# K510 register map
Vendor: Canaan; File version: 1.0
Registers are 32-bit, read-write, reset 0x0 unless marked. A register's access mark holds for its fields unless they carry their own. Offsets are from the block's base; [hi:lo] are bit positions; lines under a group give offsets from that group; {n}, {i} and the like mark numbered series; 'fields as' and 'values as' point back to an identical list.

## SYSCTL — System Control
Base 0x97000000
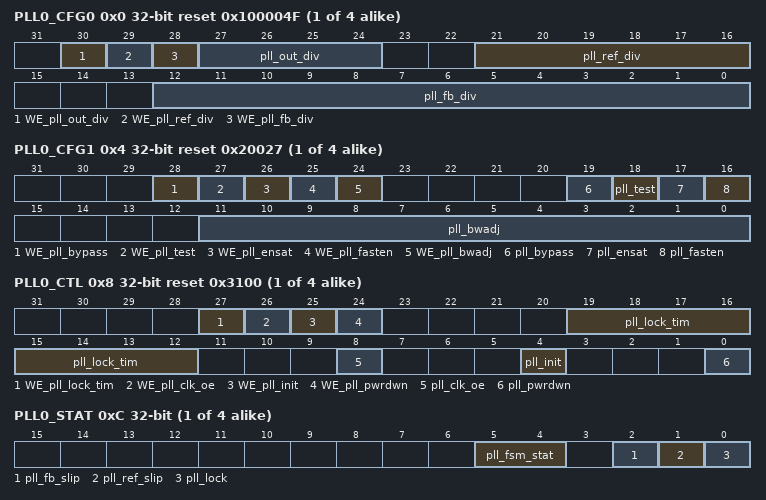
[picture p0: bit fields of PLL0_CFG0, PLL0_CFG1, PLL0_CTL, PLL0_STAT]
{0x0+0x10*i} PLL{i}_CFG0 (i=0..3) reset 0x100004F (reset mask 0x7F3F1FFFF) — PLL[i] configuration register 0
  [30] WE_pll_out_div wo — Write enable for bits [27:24] (pll_out_div)
  [29] WE_pll_ref_div wo — Write enable for bits [21:16] (pll_ref_div)
  [28] WE_pll_fb_div wo — Write enable for bits [12:0] (pll_fb_div)
  [27:24] pll_out_div — PLL[i] VCO output clock post division ratio. It is strongly suggested not to modify this value.
  [21:16] pll_ref_div — PLL[i] reference clock path division ratio.
  [12:0] pll_fb_div — PLL[i] feedback path clock division ratio.
{0x4+0x10*i} PLL{i}_CFG1 (i=0..3) reset 0x20027 — PLL[i] configuration register 1
  [28] WE_pll_bypass wo — Write enable for bit 19 (pll_bypass)
  [27] WE_pll_test wo — Write enable for bit 18 (pll_test)
  [26] WE_pll_ensat wo — Write enable for bit 17 (pll_ensat)
  [25] WE_pll_fasten wo — Write enable for bit 16 (pll_fasten)
  [24] WE_pll_bwadj wo — Write enable for bits [11:0] (pll_bwadj)
  [19] pll_bypass — PLL[i] bypass mode enable control bit.
    0=DISABLE (Disable PLL bypass mode); 1=ENABLE (Enable PLL bypass mode)
  [18] pll_test — PLL[i] test mode enable control bit.
    0=DISABLE (Disable PLL test mode); 1=ENABLE (Enable PLL test mode)
  [17] pll_ensat — PLL[i] saturation behavior enable control bit.
    0=DISABLE (Disable PLL saturation behavior); 1=ENABLE (Enable PLL saturation behavior)
  [16] pll_fasten — PLL[i] fast locking circuit enable control bit.
    0=DISABLE (Disable PLL fast locking circuit); 1=ENABLE (Enable PLL fast locking circuit)
  [11:0] pll_bwadj — PLL[i] bandwidth adjustment parameter.
{0x8+0x10*i} PLL{i}_CTL (i=0..3) reset 0x3100 — PLL[i] control register
  [27] WE_pll_lock_tim wo — Write enable for bits [19:12] (pll_lock_tim)
  [26] WE_pll_clk_oe wo — Write enable for bit 8 (pll_clk_oe)
  [25] WE_pll_init wo — Write enable for bit 4 (pll_init)
  [24] WE_pll_pwrdwn wo — Write enable for bit 0 (pll_pwrdwn)
  [19:12] pll_lock_tim — The time required for PLL[i] to reach lock state.
  [8] pll_clk_oe — PLL[i] VSO output clock enable control bit.
    0=DISABLE (Disable PLL VSO output clock); 1=ENABLE (Enable PLL VSO output clock)
  [4] pll_init wo — PLL[i] initialization trigger bit.
    0=NO_OPERATION; 1=START (Start PLL initialization sequence)
  [0] pll_pwrdwn wo — PLL[i] go power-down mode trigger bit.
    0=NO_OPERATION; 1=power_down (Put PLL[i] into power-down mode)
{0xC+0x10*i} PLL{i}_STAT (i=0..3) ro — PLL[i] status register
  [5:4] pll_fsm_stat — PLL[i] controlling FSM current status
    0=POWER_DOWN (PLL[i] is in POWER_DOWN mode); 1=RESET_PLL (PLL[i] is in RESET_PLL mode); 2=WAIT_LOCK (PLL[i] is in WAIT_LOCK mode); 3=PLL_READY (PLL[i] is in PLL_READY mode)
  [2] pll_fb_slip — This is the feedback clock path frequency/phase slip status
    0=OK (PLL working OK); 1=SLIP (There are frequency/phase slip on feedback clock)
  [1] pll_ref_slip — This is the reference clock path frequency/phase slip status
    0=OK (PLL working OK); 1=SLIP (There are frequency/phase slip on reference clock)
  [0] pll_lock — PLL[i] current lock status
    0=NOT_LOCKED (PLL[i] not in lock state); 1=LOCKED (PLL[i] in lock state)
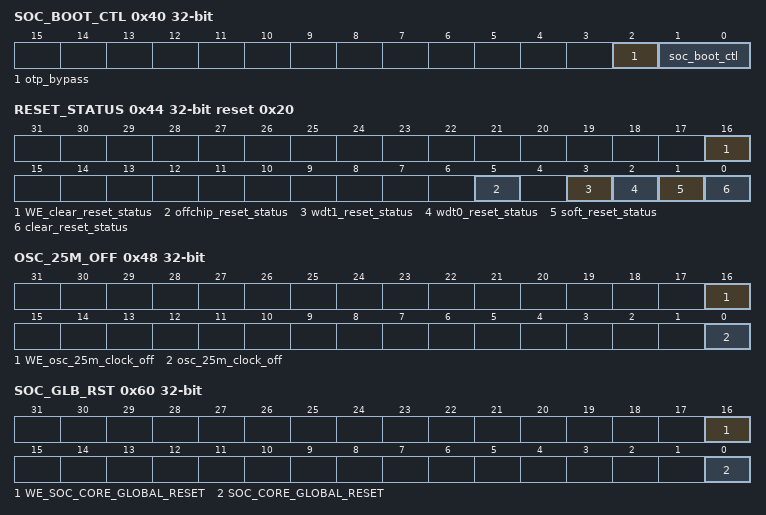
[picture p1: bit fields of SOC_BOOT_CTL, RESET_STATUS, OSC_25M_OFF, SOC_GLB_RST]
0x40 SOC_BOOT_CTL ro — SoC boot control register
  [2] otp_bypass — SoC core otp_bypass pin
    0=DISABLE (Disable OTP bypass); 1=ENABLE (Enable OTP bypass)
  [1:0] soc_boot_ctl — SoC core boot_ctl pin
    0=MODE0 (Boot mode 0: from UART); 1=MODE1 (Boot mode 1: from SD); 2=MODE2 (Boot mode 2: from SPI NAND); 3=MODE3 (Boot mode 3: from eMMC)
0x44 RESET_STATUS reset 0x20
  [16] WE_clear_reset_status wo — Write enable for bit 0 (clear_reset_status)
  [5] offchip_reset_status ro
    0=NOT_RESET (offchip reset doen't occur); 1=RESET (offchip reset occurs)
  [3] wdt1_reset_status ro
    0=NOT_RESET (WDT1 reset doen't occur); 1=RESET (WDT1 reset occurs)
  [2] wdt0_reset_status ro
    0=NOT_RESET (WDT0 reset doen't occur); 1=RESET (WDT0 reset occurs)
  [1] soft_reset_status ro
    0=NOT_RESET (Soft reset doen't occur); 1=RESET (Soft reset occurs)
  [0] clear_reset_status wo
    0=no_operation; 1=Clear all reset status
0x48 OSC_25M_OFF — OSC 25M clock off register
  [16] WE_osc_25m_clock_off wo — Write enable for bit 0 (osc_25m_clock_off)
  [0] osc_25m_clock_off
    0=ON (25m_osc enable); 1=OFF (25m_osc off)
0x60 SOC_GLB_RST wo — SoC global reset control register
  [16] WE_SOC_CORE_GLOBAL_RESET — Write enable for bit 0 (SOC_CORE_GLOBAL_RESET)
  [0] SOC_CORE_GLOBAL_RESET
    0=no_operation; 1=Reset SoC core
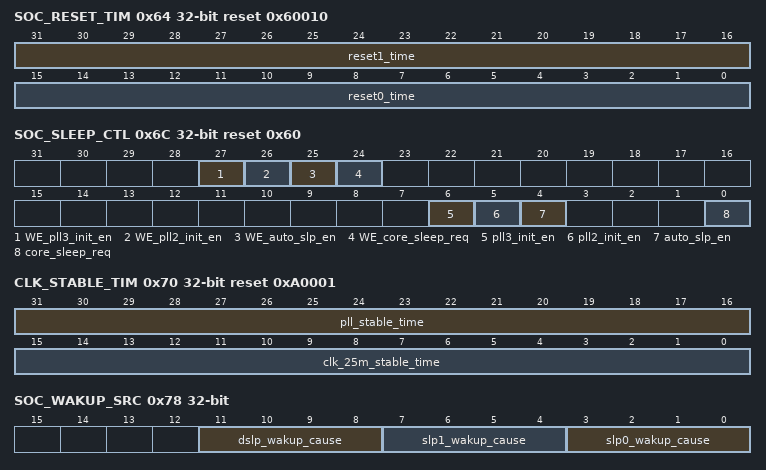
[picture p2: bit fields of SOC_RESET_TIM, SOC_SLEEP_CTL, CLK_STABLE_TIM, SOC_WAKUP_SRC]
0x64 SOC_RESET_TIM reset 0x60010 — SoC reset timing configuration register
  [31:16] reset1_time — The Max allowed time SoC after soc reset assert, then the system will enter Mission state.
  [15:0] reset0_time — The Max allowed time SoC between offchip reset and global reset assert. The time unit here is a cycle of 32KHz clock.
0x68 SOC_SLEEP_TIM reset 0x8 — SoC sleep mode timing configuration register
  [31:0] enter_sleep1_time — The Max allowed time SoC can stay in NAP mode. If no wakeup event detected, SoC core will then enter SLEEP1 mode. The time unit here is a cycle of 32KHz clock.
0x6C SOC_SLEEP_CTL reset 0x60 — SoC sleep mode control register
  [27] WE_pll3_init_en — Write enable for bit 6 (pll3_init_en)
  [26] WE_pll2_init_en — Write enable for bit 5 (pll2_init_en)
  [25] WE_auto_slp_en — Write enable for bit 4 (auto_slp_en)
  [24] WE_core_sleep_req — Write enable for bit 0 (core_sleep_req)
  [6] pll3_init_en — PLL3 auto initialization enable bit.
    0=DISABLE (Disable PLL auto initialization); 1=ENABLE (Enable PLL auto initialization)
  [5] pll2_init_en — PLL2 auto initialization enable bit.
    values as pll3_init_en
  [4] auto_slp_en — SoC core auto sleep enable control bit.
    0=DISABLE (Disable SoC core auto sleep entering feature); 1=ENABLE (Enable SoC core auto sleep entering feature)
  [0] core_sleep_req wo — SoC core go sleep request bit
    0=no_operation; 1=sleep (Request SoC core to enter SLEEP mode)
0x70 CLK_STABLE_TIM reset 0xA0001 — Clock stable timing configuration register
  [31:16] pll_stable_time — The Max allowed time SoC for PLL oscillator stable. The time unit here is a cycle of 32KHz clock.
  [15:0] clk_25m_stable_time — The Max allowed time SoC for 25MHz oscillator stable. The time unit here is a cycle of 32KHz clock.
0x74 CPU_WAKUP_TIM reset 0x2 — CPU wake-up timing configuration register
  [15:0] cpu_wakeup_time — The Max allowed time SoC can stay in WAKECPU mode. Then SoC core will enter Mission mode. The time unit here is a cycle of 32KHz clock.
0x78 SOC_WAKUP_SRC ro — SoC wake-up cause status register
  [11:8] dslp_wakup_cause — The cause of SoC waking up from DEEPSLEEP mode.
    1=RTC (SoC is woken up by RTC generate event); 4=TIMER (SoC is woken up by TIMER generate event); 8=GPIO (SoC is woken up by GPIO key pressing event)
  [7:4] slp1_wakup_cause — The cause of SoC waking up from SLEEP1 mode.
    1=RTC (SoC is woken up by RTC generate event); 2=VAD (SoC is woken up by VAD generate event); 4=TIMER (SoC is woken up by TIMER generate event); 8=GPIO (SoC is woken up by GPIO key pressing event)
  [3:0] slp0_wakup_cause — The cause of SoC waking up from SLEEP0 mode.
    values as slp1_wakup_cause
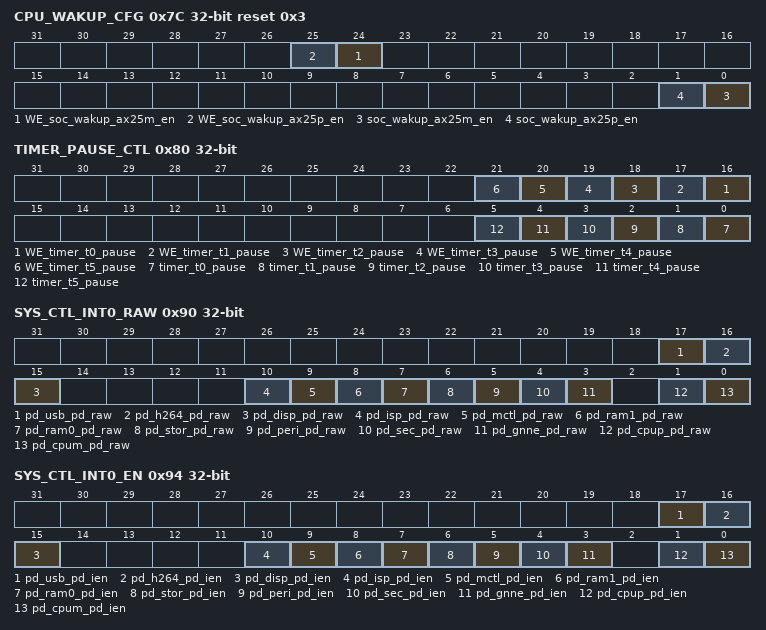
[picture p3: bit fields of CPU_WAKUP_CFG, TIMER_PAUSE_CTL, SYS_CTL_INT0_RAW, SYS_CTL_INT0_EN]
0x7C CPU_WAKUP_CFG reset 0x3 (reset mask 0x2DC6C3) — CPU wake-up (when SoC core is woken up) configuration register
  [24] WE_soc_wakup_ax25{x}_en (x=m,p; step 1) wo — Write enable for bit (soc_wakup_ax25[mp]_en)
  [0] soc_wakup_ax25{x}_en (x=m,p; step 1) — AX25M/AX25P auto wake-up enable when SoC wakes up.
    0=DISABLE (Don't wakeup when SoC waks up from SLEEP mode); 1=ENABLE (Auto Waking-up when SoC wakes up from SLEEP mode)
0x80 TIMER_PAUSE_CTL (reset mask 0x3F003F) — SoC internal Timer module's timer pause control register
  [n+16] WE_timer_t{n}_pause (n=0..5) wo — Write enable for bit (timer_t[i]_pause)
  [n] timer_t{n}_pause (n=0..5) — SoC Timer module internal timer [i] pause control bit
    0=RESUME (Resume timer [i] counting function); 1=ENABLE (Pause timer [i] counting function)
0x90 SYS_CTL_INT0_RAW — Sysctl module interrupt 0 raw status register
  [17] pd_usb_pd_raw write-1-clears — USB power domain go power-off interrupt status bit
    0=NO_INTERRUPT (No interrupt happens); 1=PENDING (PD_USB enter Power-Off state)
  [16] pd_h264_pd_raw write-1-clears — H264 power domain go power-off interrupt status bit
    0=NO_INTERRUPT (No interrupt happens); 1=PENDING (PD_H264 enter Power-Off state)
  [15] pd_disp_pd_raw write-1-clears — DISP power domain go power-off interrupt status bit
    0=NO_INTERRUPT (No interrupt happens); 1=PENDING (PD_DISP enter Power-Off state)
  [10] pd_isp_pd_raw write-1-clears — ISP power domain go power-off interrupt status bit
    0=NO_INTERRUPT (No interrupt happens); 1=PENDING (PD_ISP enter Power-Off state)
  [9] pd_mctl_pd_raw write-1-clears — Memory Controller power domain go power-off interrupt status bit
    0=NO_INTERRUPT (No interrupt happens); 1=PENDING (PD_MCTL enter Power-Off state)
  [8] pd_ram1_pd_raw write-1-clears — SRAM1 power domain go power-off interrupt status bit
    0=NO_INTERRUPT (No interrupt happens); 1=PENDING (PD_RAM1 enter Power-Off state)
  [7] pd_ram0_pd_raw write-1-clears — SRAM0 power domain go power-off interrupt status bit
    0=NO_INTERRUPT (No interrupt happens); 1=PENDING (PD_RAM0 enter Power-Off state)
  [6] pd_stor_pd_raw write-1-clears — Storage power domain go power-off interrupt status bit
    0=NO_INTERRUPT (No interrupt happens); 1=PENDING (PD_STOR enter Power-Off state)
  [5] pd_peri_pd_raw write-1-clears — Peripheral power domain go power-off interrupt status bit
    0=NO_INTERRUPT (No interrupt happens); 1=PENDING (PD_PERI enter Power-Off state)
  [4] pd_sec_pd_raw write-1-clears — Security power domain go power-off interrupt status bit
    0=NO_INTERRUPT (No interrupt happens); 1=PENDING (PD_SEC enter Power-Off state)
  [3] pd_gnne_pd_raw write-1-clears — GNNE power domain go power-off interrupt status bit
    0=NO_INTERRUPT (No interrupt happens); 1=PENDING (PD_GNNE enter Power-Off state)
  [1] pd_cpup_pd_raw write-1-clears — CPUp (AX25P) power domain go power-off interrupt status bit
    0=NO_INTERRUPT (No interrupt happens); 1=PENDING (PD_CPUp enter Power-Off state)
  [0] pd_cpum_pd_raw write-1-clears — CPUM (AX25M) power domain go power-off interrupt status bit
    0=NO_INTERRUPT (No interrupt happens); 1=PENDING (PD_CPUM enter Power-Off state)
0x94 SYS_CTL_INT0_EN — Sysctl module interrupt 0 interrupt enable register
  [all] fields
    0=DISABLE (Disable interrupt); 1=ENABLE (Enable interrupt)
  [17] pd_usb_pd_ien write-1-clears — USB power domain go power-off interrupt enable bit
  [16] pd_h264_pd_ien write-1-clears — H264 power domain go power-off interrupt enable bit
  [15] pd_disp_pd_ien write-1-clears — DISP power domain go power-off interrupt enable bit
  [10] pd_isp_pd_ien write-1-clears — ISP power domain go power-off interrupt enable bit
  [9] pd_mctl_pd_ien write-1-clears — Memory Controller power domain go power-off interrupt enable bit
  [8] pd_ram1_pd_ien write-1-clears — SRAM1 power domain go power-off interrupt enable bit
  [7] pd_ram0_pd_ien write-1-clears — SRAM0 power domain go power-off interrupt enable bit
  [6] pd_stor_pd_ien write-1-clears — Storage power domain go power-off interrupt enable bit
  [5] pd_peri_pd_ien write-1-clears — Peripheral power domain go power-off interrupt enable bit
  [4] pd_sec_pd_ien write-1-clears — Security power domain go power-off interrupt enable bit
  [3] pd_gnne_pd_ien write-1-clears — GNNE power domain go power-off interrupt enable bit
  [1] pd_cpup_pd_ien write-1-clears — CPUp (AX25P) power domain go power-off interrupt enable bit
  [0] pd_cpum_pd_ien write-1-clears — CPUm (AX25M) power domain go power-off interrupt enable bit
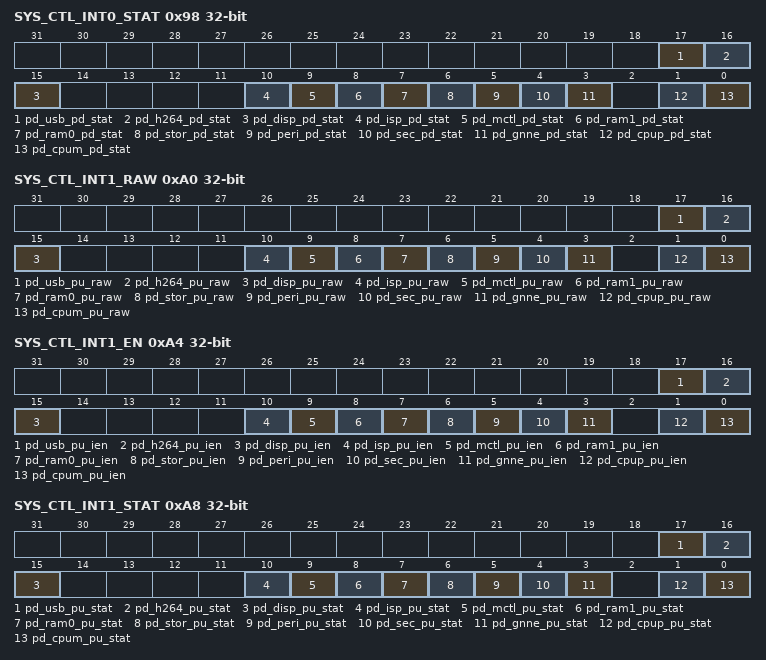
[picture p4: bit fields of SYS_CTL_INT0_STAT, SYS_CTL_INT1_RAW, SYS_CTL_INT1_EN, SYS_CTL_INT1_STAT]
0x98 SYS_CTL_INT0_STAT ro — Sysctl module interrupt 0 interrupt status register
  [all] fields
    1=NO_INTERRUPT; 0=PENDING (Interrupt happens)
  [17] pd_usb_pd_stat — USB power domain go power-off interrupt status bit
  [16] pd_h264_pd_stat — H264 power domain go power-off interrupt status bit
  [15] pd_disp_pd_stat — DISP power domain go power-off interrupt status bit
  [10] pd_isp_pd_stat — ISP power domain go power-off interrupt status bit
  [9] pd_mctl_pd_stat — MCTL power domain go power-off interrupt status bit
  [8] pd_ram1_pd_stat — SRAM1 power domain go power-off interrupt status bit
  [7] pd_ram0_pd_stat — SRAM0 power domain go power-off interrupt status bit
  [6] pd_stor_pd_stat — STOR power domain go power-off interrupt status bit
  [5] pd_peri_pd_stat — Peripheral power domain go power-off interrupt status bit
  [4] pd_sec_pd_stat — Security power domain go power-off interrupt status bit
  [3] pd_gnne_pd_stat — GNNE power domain go power-off interrupt status bit
  [1] pd_cpup_pd_stat — CPUp (AX25P) power domain go power-off interrupt status bit
  [0] pd_cpum_pd_stat — CPUm (AX25M) power domain go power-off interrupt status bit
0xA0 SYS_CTL_INT1_RAW write-1-clears — Sysctl module interrupt 1 raw status register
  [17] pd_usb_pu_raw write-1-clears — USB power domain go power-up interrupt status bit
    0=NO_INTERRUPT (No interrupt happens); 1=PENDING (PD_USB enter Power-On state)
  [16] pd_h264_pu_raw write-1-clears — H264 power domain go power-up interrupt status bit
    0=NO_INTERRUPT (No interrupt happens); 1=PENDING (PD_H264 enter Power-On state)
  [15] pd_disp_pu_raw write-1-clears — DISP power domain go power-up interrupt status bit
    0=NO_INTERRUPT (No interrupt happens); 1=PENDING (PD_DISP enter Power-On state)
  [10] pd_isp_pu_raw write-1-clears — ISP power domain go power-up interrupt status bit
    0=NO_INTERRUPT (No interrupt happens); 1=PENDING (PD_ISP enter Power-On state)
  [9] pd_mctl_pu_raw write-1-clears — Memory Controller power domain go power-up interrupt status bit
    0=NO_INTERRUPT (No interrupt happens); 1=PENDING (PD_MCTL enter Power-On state)
  [8] pd_ram1_pu_raw write-1-clears — SRAM1 power domain go power-up interrupt status bit
    0=NO_INTERRUPT (No interrupt happens); 1=PENDING (PD_RAM1 enter Power-On state)
  [7] pd_ram0_pu_raw write-1-clears — SRAM0 power domain go power-up interrupt status bit
    0=NO_INTERRUPT (No interrupt happens); 1=PENDING (PD_RAM0 enter Power-On state)
  [6] pd_stor_pu_raw write-1-clears — Storage power domain go power-up interrupt status bit
    0=NO_INTERRUPT (No interrupt happens); 1=PENDING (PD_STOR enter Power-On state)
  [5] pd_peri_pu_raw write-1-clears — Peripheral power domain go power-up interrupt status bit
    0=NO_INTERRUPT (No interrupt happens); 1=PENDING (PD_PERI enter Power-On state)
  [4] pd_sec_pu_raw write-1-clears — Security power domain go power-up interrupt status bit
    0=NO_INTERRUPT (No interrupt happens); 1=PENDING (PD_SEC enter Power-On state)
  [3] pd_gnne_pu_raw write-1-clears — GNNE power domain go power-up interrupt status bit
    0=NO_INTERRUPT (No interrupt happens); 1=PENDING (PD_GNNE enter Power-On state)
  [1] pd_cpup_pu_raw write-1-clears — CPUp (AX25P) power domain go power-up interrupt status bit
    0=NO_INTERRUPT (No interrupt happens); 1=PENDING (PD_CPUp enter Power-On state)
  [0] pd_cpum_pu_raw write-1-clears — CPUM (AX25M) power domain go power-up interrupt status bit
    0=NO_INTERRUPT (No interrupt happens); 1=PENDING (PD_CPUM enter Power-On state)
0xA4 SYS_CTL_INT1_EN — Sysctl module interrupt 1 interrupt enable register
  [all] fields
    0=DISABLE (Disable interrupt); 1=ENABLE (Enable interrupt)
  [17] pd_usb_pu_ien write-1-clears — USB power domain go power-up interrupt enable bit
  [16] pd_h264_pu_ien write-1-clears — H264 power domain go power-up interrupt enable bit
  [15] pd_disp_pu_ien write-1-clears — DISP power domain go power-up interrupt enable bit
  [10] pd_isp_pu_ien write-1-clears — ISP power domain go power-up interrupt enable bit
  [9] pd_mctl_pu_ien write-1-clears — Memory Controller power domain go power-up interrupt enable bit
  [8] pd_ram1_pu_ien write-1-clears — SRAM1 power domain go power-up interrupt enable bit
  [7] pd_ram0_pu_ien write-1-clears — SRAM0 power domain go power-up interrupt enable bit
  [6] pd_stor_pu_ien write-1-clears — Storage power domain go power-up interrupt enable bit
  [5] pd_peri_pu_ien write-1-clears — Peripheral power domain go power-up interrupt enable bit
  [4] pd_sec_pu_ien write-1-clears — Security power domain go power-up interrupt enable bit
  [3] pd_gnne_pu_ien write-1-clears — GNNE power domain go power-up interrupt enable bit
  [1] pd_cpup_pu_ien write-1-clears — CPUp (AX25P) power domain go power-up interrupt enable bit
  [0] pd_cpum_pu_ien write-1-clears — CPUm (AX25M) power domain go power-up interrupt enable bit
0xA8 SYS_CTL_INT1_STAT ro — Sysctl module interrupt 1 interrupt status register
  [all] fields
    1=NO_INTERRUPT; 0=PENDING (Interrupt happens)
  [17] pd_usb_pu_stat — USB power domain go power-up interrupt status bit
  [16] pd_h264_pu_stat — H264 power domain go power-up interrupt status bit
  [15] pd_disp_pu_stat — DISP power domain go power-up interrupt status bit
  [10] pd_isp_pu_stat — ISP power domain go power-up interrupt status bit
  [9] pd_mctl_pu_stat — MCTL power domain go power-up interrupt status bit
  [8] pd_ram1_pu_stat — SRAM1 power domain go power-up interrupt status bit
  [7] pd_ram0_pu_stat — SRAM0 power domain go power-up interrupt status bit
  [6] pd_stor_pu_stat — STOR power domain go power-up interrupt status bit
  [5] pd_peri_pu_stat — Peripheral power domain go power-up interrupt status bit
  [4] pd_sec_pu_stat — Security power domain go power-up interrupt status bit
  [3] pd_gnne_pu_stat — GNNE power domain go power-up interrupt status bit
  [1] pd_cpup_pu_stat — CPUp (AX25P) power domain go power-up interrupt status bit
  [0] pd_cpum_pu_stat — CPUm (AX25M) power domain go power-up interrupt status bit
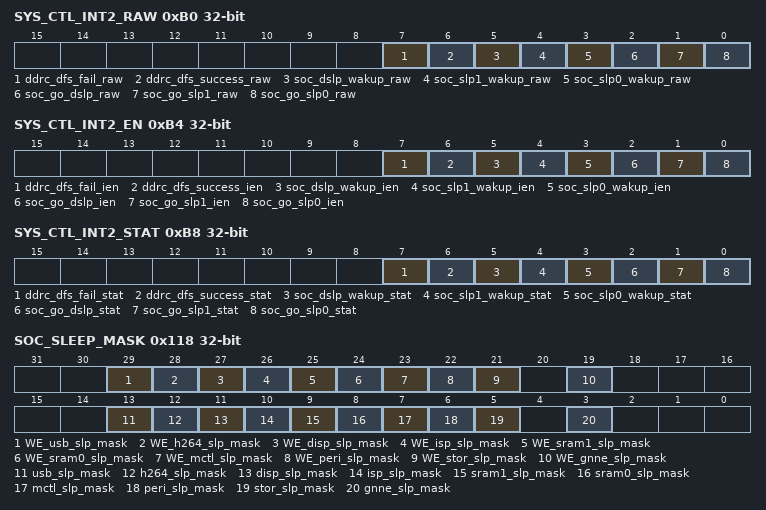
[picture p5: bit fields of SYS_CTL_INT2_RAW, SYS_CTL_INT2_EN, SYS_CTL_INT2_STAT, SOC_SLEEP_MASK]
0xB0 SYS_CTL_INT2_RAW — Sysctl module interrupt 2 raw status register
  [7] ddrc_dfs_fail_raw write-1-clears — ddrc dfs fail interrupt raw status bit
    1=NO_INTERRUPT; 0=PENDING (ddrc dfs fail)
  [6] ddrc_dfs_success_raw write-1-clears — ddrc dfs success interrupt raw status bit
    1=NO_INTERRUPT; 0=PENDING (ddrc dfs success)
  [5] soc_dslp_wakup_raw write-1-clears — SoC core wake up from DEEPSLEEP mode interrupt raw status bit
    1=NO_INTERRUPT; 0=PENDING (SoC core wake up from DEEPSLEEP mode)
  [4] soc_slp1_wakup_raw write-1-clears — SoC core wake up from SLEEP1 mode interrupt raw status bit
    1=NO_INTERRUPT; 0=PENDING (SoC core wake up from SLEEP1 mode)
  [3] soc_slp0_wakup_raw write-1-clears — SoC core wake up from SLEEP0 mode interrupt raw status bit
    1=NO_INTERRUPT; 0=PENDING (SoC core wake up from SLEEP0 mode)
  [2] soc_go_dslp_raw write-1-clears — SoC core entering DEEPSLEEP mode interrupt raw status bit
    1=NO_INTERRUPT; 0=PENDING (SoC core entering DEEPSLEEP mode)
  [1] soc_go_slp1_raw write-1-clears — SoC core entering SLEEP1 mode interrupt raw status bit
    1=NO_INTERRUPT; 0=PENDING (SoC core entering SLEEP1 mode)
  [0] soc_go_slp0_raw write-1-clears — SoC core entering SLEEP0 mode interrupt raw status bit
    1=NO_INTERRUPT; 0=PENDING (SoC core entering SLEEP0 mode)
0xB4 SYS_CTL_INT2_EN — Sysctl module interrupt 2 interrupt enable register
  [all] fields
    0=DISABLE (Disable interrupt); 1=ENABLE (Enable interrupt)
  [7] ddrc_dfs_fail_ien — ddrc dfs fail interrupt enable bit
  [6] ddrc_dfs_success_ien — ddrc dfs success interrupt enable bit
  [5] soc_dslp_wakup_ien — SoC core wake up from DEEPSLEEP mode interrupt enable bit
  [4] soc_slp1_wakup_ien — SoC core wake up from SLEEP1 mode interrupt enable bit
  [3] soc_slp0_wakup_ien — SoC core wake up from SLEEP0 mode interrupt enable bit
  [2] soc_go_dslp_ien — SoC core entering DEEPSLEEP mode interrupt enable bit
  [1] soc_go_slp1_ien — SoC core entering SLEEP1 mode interrupt enable bit
  [0] soc_go_slp0_ien — SoC core entering SLEEP0 mode interrupt enable bit
0xB8 SYS_CTL_INT2_STAT ro — Sysctl module interrupt 2 interrupt status register
  [all] fields
    0=NO_INTERRUPT; 1=PENDING (Interrupt happens)
  [7] ddrc_dfs_fail_stat — ddrc dfs fail interrupt status bit
  [6] ddrc_dfs_success_stat — ddrc dfs success interrupt status bit
  [5] soc_dslp_wakup_stat — SoC core wake up from DEEPSLEEP mode interrupt status bit
  [4] soc_slp1_wakup_stat — SoC core wake up from SLEEP1 mode interrupt status bit
  [3] soc_slp0_wakup_stat — SoC core wake up from SLEEP0 mode interrupt status bit
  [2] soc_go_dslp_stat — SoC core entering DEEPSLEEP mode interrupt status bit
  [1] soc_go_slp1_stat — SoC core entering SLEEP1 mode interrupt status bit
  [0] soc_go_slp0_stat — SoC core entering SLEEP0 mode interrupt status bit
{0x100+4i} AX25M_HART{i}_RSTVEC (i=0..1) ro — AX25M dual-core CPU hart[i] reset vector register.
  [31:0] RESET_VECTOR — AX25M dual-core CPU hart0 reset vector. After releasing reset to AX25M CPU, hart[i] will start program excution from address set here
0x108 AX25P_CORE_RSTVEC ro — AX25P processor CPU core reset vector register.
  [31:0] RESET_VECTOR — AX25P single-core CPU reset vector. After releasing reset to AX25P CPU, the core will start program excution from address set here
0x118 SOC_SLEEP_MASK — SoC sleep mode control register
  [29] WE_usb_slp_mask wo — Write enable for bit 13 (ub_slp_mask)
  [28] WE_h264_slp_mask wo — Write enable for bit 12 (h264_slp_mask)
  [27] WE_disp_slp_mask wo — Write enable for bit 11 (disp_slp_mask)
  [26] WE_isp_slp_mask wo — Write enable for bit 10 (isp_slp_mask)
  [25] WE_sram1_slp_mask wo — Write enable for bit 9 (sram1_slp_mask)
  [24] WE_sram0_slp_mask wo — Write enable for bit 8 (sram0_slp_mask)
  [23] WE_mctl_slp_mask wo — Write enable for bit 7 (mctl_slp_mask)
  [22] WE_peri_slp_mask wo — Write enable for bit 6 (peri_slp_mask)
  [21] WE_stor_slp_mask wo — Write enable for bit 5 (stor_slp_mask)
  [19] WE_gnne_slp_mask wo — Write enable for bit 3 (gnne_slp_mask)
  [13] usb_slp_mask — PD_USB sleep mask bit
    0=UNMASK (Unmask PD_USB sleep); 1=MASK (Mask PD_USB sleep)
  [12] h264_slp_mask — PD_H264 sleep mask bit
    0=UNMASK (Unmask PD_H264 sleep); 1=MASK (Mask PD_H264 sleep)
  [11] disp_slp_mask — PD_DISP sleep mask bit
    0=UNMASK (Unmask PD_DISP sleep); 1=MASK (Mask PD_DISP sleep)
  [10] isp_slp_mask — PD_ISP sleep mask bit
    0=UNMASK (Unmask PD_ISP sleep); 1=MASK (Mask PD_ISP sleep)
  [9] sram1_slp_mask — PD_SRAM1 sleep mask bit
    0=UNMASK (Unmask PD_SRAM1 sleep); 1=MASK (Mask PD_SRAM1 sleep)
  [8] sram0_slp_mask — PD_SRAM0 sleep mask bit
    0=UNMASK (Unmask PD_SRAM0 sleep); 1=MASK (Mask PD_SRAM0 sleep)
  [7] mctl_slp_mask — PD_MCTL sleep mask bit
    0=UNMASK (Unmask PD_MCTL sleep); 1=MASK (Mask PD_MCTL sleep)
  [6] peri_slp_mask — PD_PERI sleep mask bit
    0=UNMASK (Unmask PD_PERI sleep); 1=MASK (Mask PD_PERI sleep)
  [5] stor_slp_mask — PD_STOR sleep mask bit
    0=UNMASK (Unmask PD_STOR sleep); 1=MASK (Mask PD_STOR sleep)
  [3] gnne_slp_mask — PD_GNNE sleep mask bit
    0=UNMASK (Unmask PD_GNNE sleep); 1=MASK (Mask PD_GNNE sleep)
0x11C TEST_PIN_SEL — Test pin group select register
  [2:0] TEST_PIN_GROUP_SEL
    {v}=G{v} (group {v}) (v=0..6)
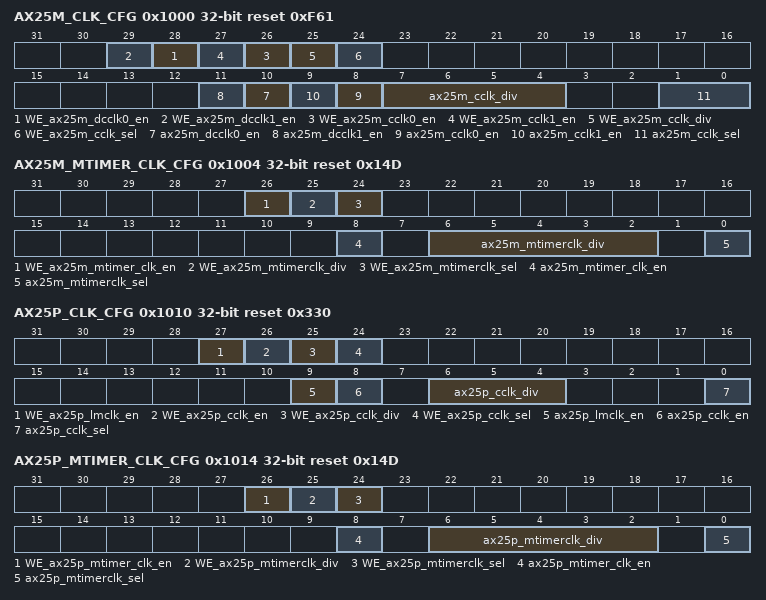
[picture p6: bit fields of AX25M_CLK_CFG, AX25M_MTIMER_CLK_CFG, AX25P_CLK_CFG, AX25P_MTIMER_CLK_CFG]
0x1000 AX25M_CLK_CFG reset 0xF61 (reset mask 0x3F000FF3) — AX25M dual-core RISCV core clock Division configure register
  [n+28] WE_ax25m_dcclk{n}_en (n=0..1) wo — Write enable for bit 10/11 (ax25m_dcclk[01]_en)
  [n+26] WE_ax25m_cclk{n}_en (n=0..1) wo — Write enable for bit 8/9 (ax25m_cclk[01]_en)
  [25] WE_ax25m_cclk_div wo — Write enable for bit [7:4] (ax25m_cclk_div)
  [24] WE_ax25m_cclk_sel wo — Write enable for bit [1:0] (ax25m_cclk_sel)
  [n+10] ax25m_dcclk{n}_en (n=0..1) — AX25M CPU dc clock enable control bit
    0=DISABLE (Disable CPU core clock output); 1=ENABLE (Enable CPU core clock output)
  [n+8] ax25m_cclk{n}_en (n=0..1) — AX25M CPU core clock enable control bit
    values as ax25m_dcclk0_en
  [7:4] ax25m_cclk_div — AX25M CPU core clock division ratio configure
    0=D12 (12/12 division); 1=D11 (11/12 division); 2=D10 (10/12 division); 3=D9 (9/12 division); 4=D8 (8/12 division); 5=D7 (7/12 division); 6=D6 (6/12 division); 7=D5 (5/12 division); 8=D4 (4/12 division); 9=D3 (3/12 division); 10=D2 (2/12 division); 11=D1 (1/12 division)
  [1:0] ax25m_cclk_sel — AX25M CPU core clock source selection
    0=PLL2_800M (800MHz source clock from PLL 2); 1=PLL0_1G (1GHz source clock from PLL 0); 2=PLL2_1_2G (1.2GHz source clock from PLL 2)
0x1004 AX25M_MTIMER_CLK_CFG reset 0x14D — AX25M dual-core RISCV core Machine Timer clock Division configure register
  [26] WE_ax25m_mtimer_clk_en — Write enable for bit 8 (ax25m_mtimer_clk_en)
  [25] WE_ax25m_mtimerclk_div — Write enable for bit [6:2] (ax25m_mtimerclk_div)
  [24] WE_ax25m_mtimerclk_sel — Write enable for bit 0 (ax25m_mtimerclk_sel)
  [8] ax25m_mtimer_clk_en — AX25M Machine Timer clock enable control bit
    0=DISABLE (Disable ax25m Machine Timer clock); 1=ENABLE (Enable ax25m Machine Timer clock)
  [6:2] ax25m_mtimerclk_div — AX25M Machine Timer clock division ratio configure
    0=D1 (no division); {v}=D{v+1} (1/{v+1} division) (v=1..31)
  [0] ax25m_mtimerclk_sel — AX25M Machine Timer clock source selection
    0=OSC_32KHz (32KHz OSC); 1=OSC_25MHz (25MHz OSC)
0x1010 AX25P_CLK_CFG reset 0x330 — AX25P single-core RISCV core clock Division configure register
  [27] WE_ax25p_lmclk_en wo — Write enable for bit 9 (ax25p_lmclk_en)
  [26] WE_ax25p_cclk_en wo — Write enable for bit 8 (ax25p_cclk_en)
  [25] WE_ax25p_cclk_div wo — Write enable for bit [6:4] (ax25p_cclk_div)
  [24] WE_ax25p_cclk_sel wo — Write enable for bit 0 (ax25p_cclk_sel)
  [9] ax25p_lmclk_en — AX25P CPU local memory clock enable control bit
    values as AX25M_CLK_CFG.ax25m_dcclk0_en
  [8] ax25p_cclk_en — AX25P CPU core clock enable control bit
    values as AX25M_CLK_CFG.ax25m_dcclk0_en
  [6:4] ax25p_cclk_div — AX25P CPU core clock division ratio configure
    0=D6 (6/6 division); 1=D5 (5/6 division); 2=D4 (4/6 division); 3=D3 (3/6 division); 4=D2 (2/6 division); 5=D1 (1/6 division)
  [0] ax25p_cclk_sel — AX25P CPU core clock source selection
    0=PLL2_792M (792MHz source clock from PLL 2); 1=PLL0_1G (1GHz source clock from PLL 0)
0x1014 AX25P_MTIMER_CLK_CFG reset 0x14D — AX25P single-core RISCV core Machine Timer clock Division configure register
  [26] WE_ax25p_mtimer_clk_en — Write enable for bit 8 (ax25p_mtimer_clk_en)
  [25] WE_ax25p_mtimerclk_div — Write enable for bit [6:2] (ax25p_mtimerclk_div)
  [24] WE_ax25p_mtimerclk_sel — Write enable for bit 0 (ax25p_mtimerclk_sel)
  [8] ax25p_mtimer_clk_en — AX25P Machine Timer clock enable control bit
    values as AX25M_MTIMER_CLK_CFG.ax25m_mtimer_clk_en
  [6:2] ax25p_mtimerclk_div — AX25P Machine Timer clock division ratio configure
    0=D1 (no division); {v}=D{v+1} (1/{v+1} division) (v=1..31)
  [0] ax25p_mtimerclk_sel — AX25P Machine Timer clock source selection
    0=OSC_32KHz (32KHz OSC); 1=OSC_25MHz (25MHz OSC)
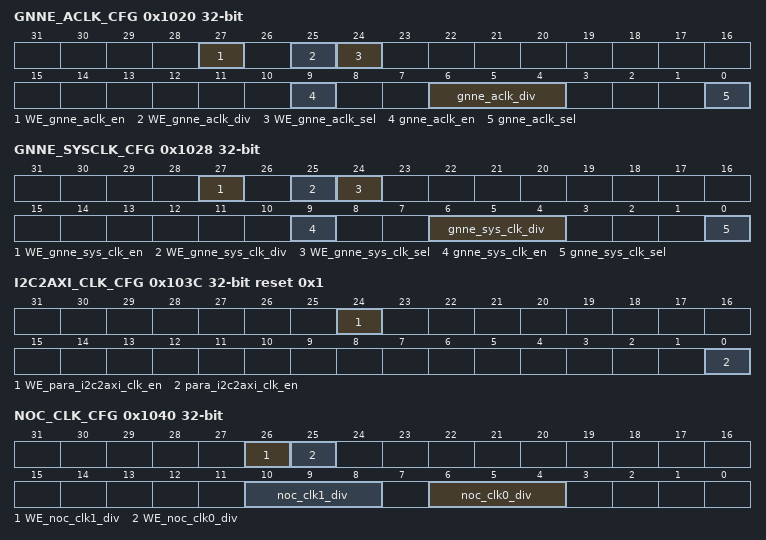
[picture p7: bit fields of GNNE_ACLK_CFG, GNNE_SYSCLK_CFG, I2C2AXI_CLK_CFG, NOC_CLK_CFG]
0x1020 GNNE_ACLK_CFG — GNNE axi clock configure register
  [27] WE_gnne_aclk_en wo — Write enable for bit 9 (gnne_aclk_en)
  [25] WE_gnne_aclk_div wo — Write enable for bits [6:4] (gnne_aclk_div)
  [24] WE_gnne_aclk_sel wo — Write enable for bit 0 (gnne_aclk_sel)
  [9] gnne_aclk_en — GNNE system axi master clock enable control bit
    0=DISABLE (Disable GNNE system axi master clock output); 1=ENABLE (Enable GNNE system axi master clock output)
  [6:4] gnne_aclk_div — GNNE axi port clock division ratio configure
    values as AX25P_CLK_CFG.ax25p_cclk_div
  [0] gnne_aclk_sel — GNNE axi master clock source selection
    0=PLL0_500M (500MHz source clock from PLL 0 div2); 1=PLL1_667M (667MHz source clock from PLL 1 div2)
0x1028 GNNE_SYSCLK_CFG — GNNE system clock configure register
  [27] WE_gnne_sys_clk_en wo — Write enable for bit 9 (gnne_sys_clk_en)
  [25] WE_gnne_sys_clk_div wo — Write enable for bits [6:4] (gnne_sys_clk_div)
  [24] WE_gnne_sys_clk_sel wo — Write enable for bit 0 (gnne_sys_clk_sel)
  [9] gnne_sys_clk_en — GNNE system main function clock enable control bit
    0=DISABLE (Disable GNNE system main function clock output); 1=ENABLE (Enable GNNE system main function clock output)
  [6:4] gnne_sys_clk_div — GNNE system main function clock division ratio configure
    values as AX25P_CLK_CFG.ax25p_cclk_div
  [0] gnne_sys_clk_sel — GNNE main function clock source selection
    values as GNNE_ACLK_CFG.gnne_aclk_sel
0x103C I2C2AXI_CLK_CFG reset 0x1 — I2C2AXI clock configure register
  [24] WE_para_i2c2axi_clk_en wo — Write enable for bit 0 (para_i2c2axi_clk_en)
  [0] para_i2c2axi_clk_en — I2C2AXI clock enable control
    0=DISABLE (Disable I2C2AXI clock); 1=ENABLE (Enable I2C2AXI clock)
0x1040 NOC_CLK_CFG — NOC bus clock Division and configure register
  [26] WE_noc_clk1_div wo — Write enable for bits [10:8] (noc_clk1_div)
  [25] WE_noc_clk0_div wo — Write enable for bits [6:4] (noc_clk0_div)
  [4n+6:4n+4] noc_clk{n}_div (n=0..1) — NOC domain[i] bus clock division ratio configure
    values as AX25P_CLK_CFG.ax25p_cclk_div
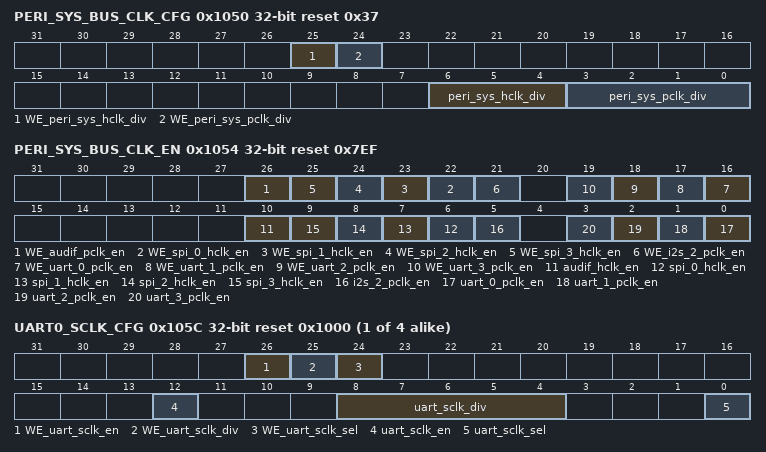
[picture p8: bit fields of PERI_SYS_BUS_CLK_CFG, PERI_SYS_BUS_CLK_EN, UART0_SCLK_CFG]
0x1050 PERI_SYS_BUS_CLK_CFG reset 0x37 — Peripheral subsystem modules bus IF clock configure register
  [25] WE_peri_sys_hclk_div wo — Write enable for bits [6:4] (peri_sys_hclk_div)
  [24] WE_peri_sys_pclk_div wo — Write enable for bits [3:0] (peri_sys_pclk_div)
  [6:4] peri_sys_hclk_div — Peripheral system AHB hclk division ratio configure
    {v}=D{v+1} (1/{v+1} division) (v=1..7)
  [3:0] peri_sys_pclk_div — Peripheral system APB pclk division ratio configure
    {v}=D{v+1} (1/{v+1} division) (v=3..15)
0x1054 PERI_SYS_BUS_CLK_EN reset 0x7EF (reset mask 0x7EF07EF) — Peripheral subsystem modules bus IF clock enable register
  [26] WE_audif_pclk_en wo — Write enable for bit 10 (audif_pclk_en)
  [n+22] WE_spi_{n}_hclk_en (n=0..3) wo — Write enable for bit 6-9 (spi_[0-3]_hclk_en)
  [21] WE_i2s_2_pclk_en wo — Write enable for bit 5 (i2s_2_pclk_en)
  [n+16] WE_uart_{n}_pclk_en (n=0..3) wo — Write enable for bit 0-3 (uart_[0-3]_pclk_en)
  [10] audif_hclk_en — Audio data interface slave APB port clock enable control
    0=DISABLE (Disable AUD_IF slave APB port clock); 1=ENABLE (Enable AUD_IF slave APB port clock)
  [n+6] spi_{n}_hclk_en (n=0..3) — SPI host [i] slave AHB interface clock enable control
    0=DISABLE (Disable SPI [i] slave AHB interface clock); 1=ENABLE (Enable SPI [i] slave AHB interface clock)
  [5] i2s_2_pclk_en — I2S 2 slave APB interface clock enable control
    0=DISABLE (Disable I2S 2 slave APB port clock); 1=ENABLE (Enable I2S 2 slave APB port clock)
  [n] uart_{n}_pclk_en (n=0..3) — UART host [i] slave APB interface clock enable control
    0=DISABLE (Disable UART [i] slave APB port clock); 1=ENABLE (Enable UART [i] slave APB port clock)
{0x105C+4i} UART{i}_SCLK_CFG (i=0..3) reset 0x1000 — UART[i] host module serial interface clock configure register
  [26] WE_uart_sclk_en wo — Write enable for bit 12 (uart_sclk_en)
  [25] WE_uart_sclk_div wo — Write enable for bit [8:4] (uart_sclk_div)
  [24] WE_uart_sclk_sel wo — Write enable for bit 0 (uart_sclk_sel)
  [12] uart_sclk_en wo — UART[i] host module serial clock enable control bit
    0=DISABLE (disable uart_sclk_output); 1=ENABLE (enable uart_sclk_output)
  [8:4] uart_sclk_div — UART[i] host module serial clock division ratio configure
    0=D1 (no division); {v}=D{v+1} (1/{v+1} division) (v=1..31)
  [0] uart_sclk_sel — UART[i] host module serial clock source selection
    0=OSCILLATOR (25MHz clock from oscillator); 1=PLL (25MHz clock from PLL)
0x1070 I2S2_SCLK_CFG — I2S 2 slave module serial interface clock configure register
{0x1074+4i} SPI{i}_SCLK_CFG (i=0..3) — SPI[i] host module serial interface clock configure register
0x1088 AUDIF_SCLK_CFG — Audio interface module serial clock configure register
0x108C AUDIF_DEVCLK_CFG — Audio device clock configure register
0x1090 SEC_SYS_BUS_CLK_CFG — Security Subsystem bus interface clock configure register
0x1094 SEC_SYS_BUS_CLK_EN — Security Subsystem modules bus interface clock control register
0x1098 OTP_CLK_EN — OTP modules clock control register
0x10A0 SRAM_BUS_CLK_EN — SRAM block 0/1 bus clock enable control register
0x10B0 SOC_CTL_PCLK_EN — SOC Control Units slave APB clock enable control register
0x10B4 SOC_CTL_PCLK_EN1 — SOC Control Units slave APB clock enable control register
{0x10B8+4i} I2C{i}_ICCLK_CFG (i=0..6) — I2C[i] host module serial clock configure register
{0x10D4+4i} WDT{i}_TCLK_CFG (i=0..2) — WDT[i] module tick clock configure register
0x10E0 TIMER_TCLK_SRC — System Timer module tick clocks source configure register
0x10E4 TIMER_TCLK_CFG — System Timer module tick clocks division configure register
0x10E8 TIMER_TCLK_CFG1 — System Timer module tick clocks division configure register
0x10EC VAD_SCLK_CFG — VAD module audio data serial clock configure register
0x1100 STOR_SYS_BUS_CLK_EN — Storage subsystem modules bus IF clock enable register
0x1104 EMAC_TRX_CLK_CFG — EMAC-PHY interface transceiver clock configure register
0x1108 SD_CARD_CLK_CFG — EMAC-PHY interface transceiver clock configure register
0x110C SENSOR_CLK_EN — SENSOR clock enable register
0x1110 ISP_SYS_PCLK_EN — ISP system APB clock enable control register
0x1114 ISP_SYS_ACLK_EN — ISP system APB clock enable control register
0x1118 DISP_SYS_PCLK_EN — DISP system APB clock enable control register
0x111C DISP_SYS_ACLK_EN — DISP system APB clock enable control register
0x1120 TPG_PIXEL_CLK_CFG — VI module tpg pixel clock configure register
{0x1124+4i} CSI{i}_PIXEL_CLK_CFG (i=0..1) — CSI[i] module pixel clock configure register
0x1134 DISP_PIXEL_CLK_CFG — DISP module pixel clock configure register
{0x113C+4i} CSI{i}_SYS_CLK_CFG (i=0..1) — CSI[i] module system clock configure register
0x114C DSI_SYS_CLK_CFG — DSI module system clock configure register
0x1150 H264_ACLK_EN — H264 module AXI clock enable control register
0x1154 USB_CLK_EN — USB host module clock enable control register
0x1158 TXDPHY_CLK_EN — MIPI TXDPHY clock enable control register
0x115C RXDPHY_CLK_EN — MIPI RXDPHY clock enable control register
0x1160 MEM_CTL_CMD_FIFO — Memory Controller DFS Command FIFO
0x1164 MEM_CTL_CMD_FIFO_STS — Memory Controller DFS Command FIFO STATUS
0x1168 MEM_CTL_CLK_CFG — Memory Controller clock configuration register
0x116C MEM_CTL_DFS_CFG — Memory Controller clock DFS configuration register
0x1170 MEM_CTL_CMD_FIFO_FLUSH — Memory Controller DFS Command FIFO FLUSH
0x2000 AX25M_RST_TIM — AX25M dual-core RISCV reset timing control register
0x2010 AX25P_RST_TIM — AX25P single-core RISCV reset timing control register
0x2014 AX25P_RST_CTL — AX25P single-core RISCV reset control register
0x2028 GNNE_RST_TIM — GNNE reset timing control register
0x202C GNNE_RST_CTL — GNNE reset control register
0x2040 SOC_CTL_RST_CTL — SOC Control subsystem reseting control register
0x2044 SOC_CTL_RST_CTL1 — SOC Control subsystem reseting control register
0x2050 PERI_SYS_RST_TIM — Peripheral subsystem reset timing control register
0x2054 UART_RST_TIM — UART host module reset timing control register
{0x2058+4i} UART{i}_RST_CTL (i=0..3) — UART[i] host module reset control register
  [31] uart_rst_done write-1-clears — UART[i] host module reseting done status bit. . Writing '1' to clear this status bit.
    0=NO_EVENT; 1=DONE (module reseting done)
0x2068 I2S_RST_TIM — I2S slave module reset timing control register
0x206C I2S2_RST_CTL — I2S 2 slave module reset control register
0x2070 SPI_RST_TIM — SPI module reset timing control register
{0x2074+4i} SPI{i}_RST_CTL (i=0..2) — SPI {i} host module reset control register
0x2080 SPI3_RST_CTL — SPI 3 slave module reset control register
0x2084 AUDIF_RST_TIM — Audio Interface module reset timing control register
0x2088 AUDIF_RST_CTL — Audio Interface module reset control register
0x208C SEC_SYS_RST_TIM — Security subsystem reset timing control register
0x2090 SHA_RST_TIM — SHA module reset timing control register
0x2094 SHA_RST_CTL — SHA module reset control register
0x2098 AES_RST_TIM — AES module reset timing control register
0x209C AES_RST_CTL — AES module reset control register
0x20A0 RSA_RST_TIM — RSA module reset timing control register
0x20A4 RSA_RST_CTL — RSA module reset control register
0x20A8 ROM_RST_TIM — ROM module reset timing control register
0x20AC ROM_RST_CTL — ROM module reset control register
0x20B0 OTP_RST_TIM — OTP module reset timing control register
0x20B4 OTP_RST_CTL — OTP module reset control register
0x20C0 STOR_SYS_RST_TIM — Storage subsystem reset timing control register
0x20C4 SDCTL_RST_TIM — SD host controllers reset timing control register
{0x20C8+4i} SDC{i}_RST_CTL (i=0..2) — SD host controller {i} reset control register
0x20D4 DMAC_RST_TIM — DMA controllers reset timing control register
0x20D8 PERI_DMA_RST_CTL — Peripheral DMAC reset control register
0x20DC SYS_DMA_RST_CTL — Memory DMAC reset control register
0x20E0 EMAC_RST_TIM — EMAC host controllers reset timing control register
0x20E4 EMAC_RST_CTL — EMAC host controllers reset control register
0x20E8 SDIO_RST_TIM — SDIO slave controller reset timing control register
0x20EC SDIO_RST_CTL — SD slave controllers reset control register
0x20F0 MCTL_RST_TIM — Memory controller reset timing control register
0x20F4 MCTL_RST_CTL — Memory controller module reset control register
0x2100 SRAM0_RST_TIM — SRAM block 0 reset timing control register
0x2104 SRAM0_RST_CTL — SRAM block 0 module reset control register
0x2110 SRAM1_RST_TIM — SRAM block 1 reset timing control register
0x2114 SRAM1_RST_CTL — SRAM block 1 module reset control register
0x2118 ISP_SYS_RST_TIM — Video subsystem reset timing control register
0x211C ISP_RST_TIM — ISP module reset timing control register
0x2124 ISP_F2K_RST_CTL — ISP_F2K module reset control register
0x2128 ISP_R2K_RST_CTL — ISP_R2K module reset control register
0x212C ISP_TOF_RST_CTL — ISP_TOF module reset control register
0x2130 CSI_RST_TIM — CSI module reset timing control register
0x2134 CSI0_RST_CTL — CSI0 module reset control register
0x2138 CSI1_RST_CTL — CSI1 module reset control register
0x2144 SENSOR_RST_TIM — SENSOR reset timing control register
0x2148 SENSOR_RST_CTL — SENSOR reset control register
0x214C VI_RST_TIM — VI module reset timing control register
0x2150 VI_RST_CTL — VI module reset control register
0x2154 MFBC_RST_TIM — MFBC module reset timing control register
0x2158 MFBC_RST_CTL — MFBC module reset control register
0x215C DISP_SYS_RST_TIM — Display subsystem reset timing control register
0x2160 DSI_RST_TIM — DSI module reset timing control register
0x2164 DSI_RST_CTL — DSI module reset control register
0x2168 BT1120_RST_TIM — BT1120 module reset timing control register
0x216C BT1120_RST_CTL — BT1120 module reset control register
0x2170 TWOD_RST_TIM — TWOD module reset timing control register
0x2174 TWOD_RST_CTL — TWOD module reset control register
0x2178 VO_RST_TIM — VO module reset timing control register
0x217C VO_RST_CTL — VO module reset control register
0x2180 H264_RST_TIM — H264 module reset timing control register
0x2184 H264_RST_CTL — H264 module reset control register
0x2188 USB_RST_TIM — USB module reset timing control register
0x218C USB_RST_CTL — USB module reset control register
0x2190 MIPI_CORNER_RST_TIM — MIPI CORNER module reset timing control register
0x2194 MIPI_CORNER_RST_CTL — MIPI CORNER module reset control register
0x2198 DDR_PHY_RST_CTL — DDR PHY reset control register
0x3000 AX25M_PWR_TIM — AX25M dual-core processor power controller timing register
0x3004 AX25M_LPI_TIM — AX25M domain NOC power controller LPI timing register
0x3008 AX25M_LPI_CTL — AX25M NOC power controller low-power interface control register
0x300C AX25M_PWR_CTL — AX25M power domain power status control register
0x3010 AX25M_LPI_STAT — AX25M NOC power controller low-power interface status register
0x3014 AX25M_PWR_STAT — AX25M power domain current power status register
0x3018 AX25M_WFI_TIM — AX25M dual-core processor WFI signal waiting timeout configure register
0x3020 AX25P_PWR_TIM — AX25P single-core processor power controller timing register
0x3024 AX25P_LPI_TIM — AX25P domain NOC power controller LPI timing register
0x3028 AX25P_LPI_CTL — AX25P NOC power controller low-power interface control register
0x302C AX25P_PWR_CTL — AX25P power domain power state control register
0x3030 AX25P_LPI_STAT — AX25P NOC power controller low-power interface status register
0x3034 AX25P_PWR_STAT — AX25P power domain current power status register
0x3038 AX25P_WFI_TIM — AX25P processor WFI signal waiting timeout configure register
0x3060 GNNE_PWR_TIM — GNNE power controller timing register
0x3064 GNNE_LPI_TIM — GNNE power domain NOC power controller LPI timing register
0x3068 GNNE_LPI_CTL — GNNE power domain NOC power controller low- power interface control register
0x306C GNNE_PWR_CTL — GNNE power domain power state control register
0x3070 GNNE_LPI_STAT — GNNE NOC power controller low-power interface status register
0x3074 GNNE_PWR_STAT — GNNE power domain current power status register
0x3080 SEC_PWR_TIM — Security subsystem domain power controller timing register
0x3084 SEC_LPI_TIM — Security subsystem domain NOC power controller LPI timing register
0x3088 SEC_LPI_CTL — Security subsystem NOC power controller low- power interface control register
0x308C SEC_PWR_CTL — Security subsys power domain power state control register
0x3090 SEC_LPI_STAT — Security subsystem NOC power controller low- power interface status register
0x3094 SEC_PWR_STAT — Security subsystem power domain current power status register
0x30A0 STOR_PWR_TIM — Storage subsystem domain power controller timing register
0x30A4 STOR_LPI_TIM — Storage subsystem domain NOC power controller LPI timing register
0x30A8 STOR_LPI_CTL — Storage subsystem NOC power controller low- power interface control register
0x30AC STOR_PWR_CTL — Storage subsystem power domain power state control register
0x30B0 STOR_LPI_STAT — Storage subsystem NOC power controller low- power interface status register
0x30B4 STOR_PWR_STAT — Storage subsystem power domain current power status register
0x30C0 PERI_PWR_TIM — Peripheral subsystem domain power controller timing register
0x30C4 PERI_LPI_TIM — Peripheral subsystem domain NOC power controller LPI timing register
0x30C8 PERI_LPI_CTL — Peripheral subsystem NOC power controller low- power interface control register
0x30CC PERI_PWR_CTL — Peripheral subsystem power domain power state control register
0x30D0 PERI_LPI_STAT — Peripheral subsystem NOC power controller low- power interface status register
0x30D4 PERI_PWR_STAT — Peripheral subsystem power domain current power status register
0x30E0 MCTL_PWR_TIM0 — System Memory contorller power controller timing register
0x30E4 MCTL_PWR_TIM1 — System Memory contorller power controller timing register
0x30E8 MCTL_LPI_TIM — Memory Controller domain NOC power controller LPI timing register
0x30EC MCTL_LPI_CTL — Memory Controller domain NOC power controller low-power interface control register
0x30F0 MCTL_PWR_CTL — Memory Controller power domain power status control register
0x30F4 MCTL_LPI_STAT — Memory Controller NOC power controller low- power interface status register
0x30F8 MCTL_PWR_STAT — Memory Controller power domain current power status register
0x3100 SRAM0_PWR_TIM — System SRAM block 0 power controller timing register
0x3104 SRAM0_LPI_TIM — System SRAM block 0 domain NOC power controller LPI timing register
0x3108 SRAM0_LPI_CTL — System SRAM block 0 domain NOC power controller low-power interface control register
0x310C SRAM0_PWR_CTL — System SRAM block 0 power domain power status control register
0x3110 SRAM0_LPI_STAT — System SRAM block 0 NOC power controller low- power interface status register
0x3114 SRAM0_PWR_STAT — System SRAM block 0 power domain current power status register
0x3120 SRAM1_PWR_TIM — System SRAM block 1 power controller timing register
0x3124 SRAM1_LPI_TIM — System SRAM block 1 domain NOC power controller LPI timing register
0x3128 SRAM1_LPI_CTL — System SRAM block 1 domain NOC power controller low-power interface control register
0x312C SRAM1_PWR_CTL — System SRAM block 1 power domain power status control register
0x3130 SRAM1_LPI_STAT — System SRAM block 1 NOC power controller low- power interface status register
0x3134 SRAM1_PWR_STAT — System SRAM block 1 power domain current power status register
0x3160 DISP_PWR_TIM — Display System power controller timing register
0x3164 DISP_LPI_TIM — System DISP domain NOC power controller LPI timing register
0x3168 DISP_LPI_CTL — System DISP domain NOC power controller low- power interface control register
0x316C DISP_PWR_CTL — System DISP power domain power status control register
0x3170 DISP_LPI_STAT — System DISP NOC power controller low-power interface status register
0x3174 DISP_PWR_STAT — System DISP power domain current power status register
0x3180 H264_PWR_TIM — System H264 power controller timing register
0x3184 H264_LPI_TIM — System H264 domain NOC power controller LPI timing register
0x3188 H264_LPI_CTL — System H264 domain NOC power controller low- power interface control register
0x318C H264_PWR_CTL — System H264 power domain power status control register
0x3190 H264_LPI_STAT — System H264 NOC power controller low-power interface status register
0x3194 H264_PWR_STAT — System H264 power domain current power status register
0x31A0 USB_PWR_TIM — System USB power controller timing register
0x31A4 USB_LPI_TIM — System USB domain NOC power controller LPI timing register
0x31A8 USB_LPI_CTL — System USB domain NOC power controller low- power interface control register
0x31AC USB_PWR_CTL — System USB power domain power status control register
0x31B0 USB_LPI_STAT — System USB NOC power controller low-power interface status register
0x31B4 USB_PWR_STAT — System USB power domain current power status register
0x31C0 ISP_PWR_TIM — System ISP power controller timing register
0x31C4 ISP_LPI_TIM — System ISP domain NOC power controller LPI timing register
0x31C8 ISP_LPI_CTL — System ISP domain NOC power controller low- power interface control register
0x31CC ISP_PWR_CTL — System ISP power domain power status control register
0x31D0 ISP_LPI_STAT — ISP NOC power controller low-power interface status register
0x31D4 ISP_PWR_STAT — ISP power domain current power status register
0x3258 PWR_DOM_GRP_EN — power domain group repair en
0x325C REPAIR_STATUS — power domain group repair status
0x3260 AX25M_REPAIR_TIM — AX25M power domain repair timer register
0x3264 AX25P_REPAIR_TIM — AX25P power domain repair timer register
0x3268 GNNE_REPAIR_TIM — GNNE power domain repair timer register
0x326C SRAM0_REPAIR_TIM — SRAM0 power domain repair timer register
0x3270 SRAM1_REPAIR_TIM — SRAM1 power domain repair timer register
0x3274 ISP_SYS_REPAIR_TIM — ISP_SYS power domain repair timer register
